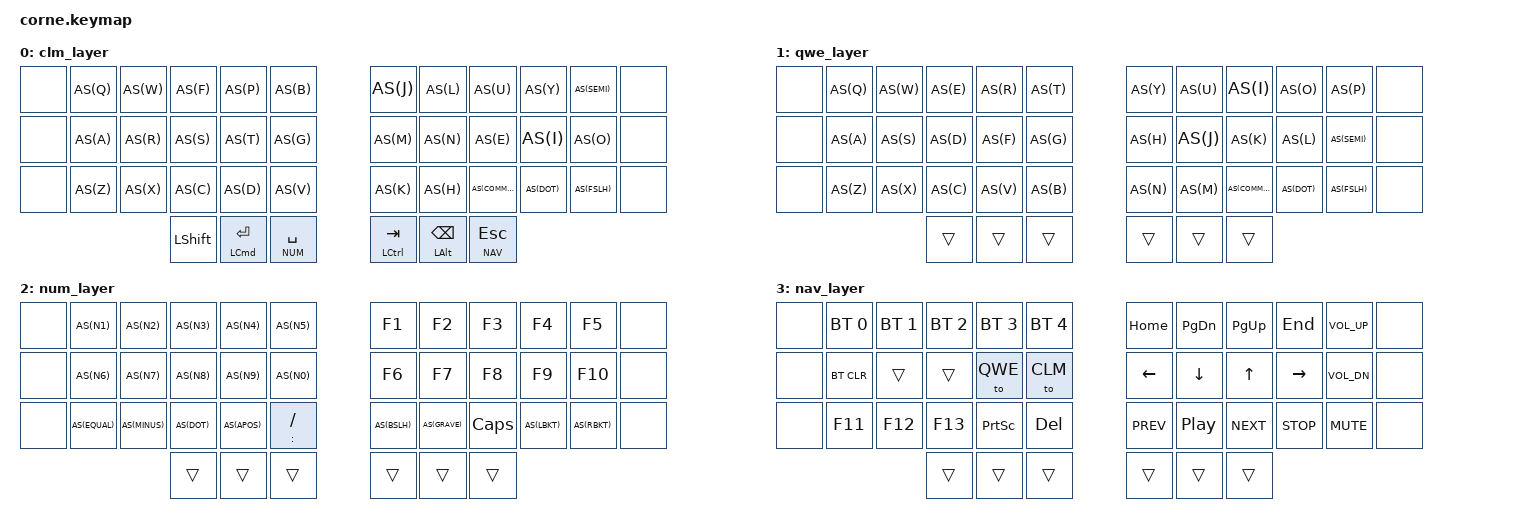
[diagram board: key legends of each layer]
/*
 * Copyright (c) 2026 ISorokin Info
 * ig40in@gmail.com
 *
 */

#include <behaviors.dtsi>
#include <dt-bindings/zmk/keys.h>
#include <dt-bindings/zmk/bt.h>
// #include <dt-bindings/zmk/outputs.h>

// Layers
#define CLM 0
#define QWE 1
#define NUM 2
#define NAV 3

#define AS(keycode) &as LS(keycode) keycode     // Autoshift Macro

/ {
    behaviors {
        as: auto_shift {
            compatible = "zmk,behavior-hold-tap";
            label = "AUTO_SHIFT";
            #binding-cells = <2>;
            tapping_term_ms = <175>;
            quick_tap_ms = <0>;
            flavor = "tap-preferred";
            bindings = <&kp>, <&kp>;
        };
    };

        keymap {
                compatible = "zmk,keymap";


                clm_layer {
                        bindings = <
&none  AS(Q)        AS(W)      AS(F)       AS(P)      AS(B)         AS(J)     AS(L)      AS(U)       AS(Y)      AS(SEMI)      &none   
&none  AS(A)        AS(R)      AS(S)       AS(T)      AS(G)         AS(M)     AS(N)      AS(E)       AS(I)      AS(O)   &none  
&none  AS(Z)        AS(X)      AS(C)       AS(D)      AS(V)         AS(K)     AS(H)      AS(COMMA)   AS(DOT)    AS(FSLH)   &none 
                    /* &mt LSHFT ESC  &kp LCMD   &mt LCTRL TAB     &lt NUM SPACE    &mt LALT BSPC  &lt NAV RET    */
                    /* &mt LSHFT ESC  &kp LCMD   &mt LCTRL TAB     &lt NUM SPACE    &mt LALT BSPC  &lt NAV RET    */
                    &kp LSHFT  &mt LCMD RET   &lt NUM SPACE     &mt LCTRL TAB    &mt LALT BSPC  &lt NAV ESC   
                        >;
                };

                qwe_layer {
                        bindings = <
&none  AS(Q)        AS(W)      AS(E)       AS(R)      AS(T)         AS(Y)     AS(U)      AS(I)       AS(O)      AS(P)      &none   
&none  AS(A)        AS(S)      AS(D)       AS(F)      AS(G)         AS(H)     AS(J)      AS(K)       AS(L)      AS(SEMI)   &none  
&none  AS(Z)        AS(X)      AS(C)       AS(V)      AS(B)         AS(N)     AS(M)      AS(COMMA)   AS(DOT)    AS(FSLH)   &none 
                    /* &mt LSHFT ESC  &kp LCTRL   &mt LCMD SPACE     &lt NUM TAB    &mt LALT BSPC  &lt NAV RET    */
                              &trans    &trans     &trans        &trans    &trans     &trans      
                        >;
                };
/*
                num_layer {
                        bindings = <
&none  &kp F1    &kp F2     &kp F3     &kp F4     &kp F5     AS(N1)    AS(N2)     AS(N3)     AS(N4)     AS(N5)        &none       
&none  &kp F6    &kp F7     &kp F8     &kp F9     &kp F10    AS(N6)    AS(N7)     AS(N8)     AS(N9)     AS(N0)        &none       
&none  &kp F11   &kp F12    &kp CAPS   AS(APOS)   AS(GRAVE)  AS(BSLH)  AS(MINUS)  AS(EQUAL)  AS(LBKT)   AS(RBKT)      &none       
                              &trans    &trans     &trans        &trans    &trans     &trans      
                        >;
                };
*/
                num_layer {
                        bindings = <
&none  AS(N1)    AS(N2)     AS(N3)     AS(N4)     AS(N5)        &kp F1    &kp F2     &kp F3     &kp F4     &kp F5     &none       
&none  AS(N6)    AS(N7)     AS(N8)     AS(N9)     AS(N0)        &kp F6    &kp F7     &kp F8     &kp F9     &kp F10    &none       
&none  AS(EQUAL) AS(MINUS)  AS(DOT)    AS(APOS)   &mt COLON FSLH  AS(BSLH)  AS(GRAVE)  &kp CAPS   AS(LBKT)   AS(RBKT)   &none       
                              &trans    &trans     &trans        &trans    &trans     &trans      
                        >;
                };

                nav_layer {
                        bindings = <
&none  &bt BT_SEL 0  &bt BT_SEL 1  &bt BT_SEL 2  &bt BT_SEL 3  &bt BT_SEL 4   &kp HOME   &kp PG_DN  &kp PG_UP  &kp END    &kp C_VOL_UP  &none
&none  &bt BT_CLR    &trans        &trans        &to QWE       &to CLM        &kp LEFT   &kp DOWN   &kp UP     &kp RIGHT  &kp C_VOL_DN  &none
&none  &kp F11       &kp F12       &kp F13       &kp PSCRN     &kp DEL        &kp C_PREV &kp C_PP   &kp C_NEXT &kp C_STOP &kp C_MUTE    &none
                              &trans    &trans     &trans        &trans     &trans     &trans      
                        >;
                };


        };
};
